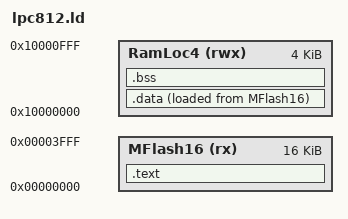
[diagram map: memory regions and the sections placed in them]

MEMORY
{
  /* Define each memory region */
  MFlash16 (rx) : ORIGIN = 0x0, LENGTH = 0x4000 /* 16k */
  RamLoc4 (rwx) : ORIGIN = 0x10000000, LENGTH = 0x1000 /* 4k */

}
  /* Define a symbol for the top of each memory region */
  __top_MFlash16 = 0x0 + 0x4000;
  __top_RamLoc4 = 0x10000000 + 0x1000;


ENTRY(ResetISR)

SECTIONS
{

    /* MAIN TEXT SECTION */    
    .text : ALIGN(4)
    {
        FILL(0xff)
        KEEP(*(.isr_vector))
        
        *(.after_vectors*)
        
        *(.text*)
        *(.rodata .rodata.*)
        . = ALIGN(4);
        
    } > MFlash16
    
    _etext = .;
        
    
    /* MAIN DATA SECTION */
    
    .data : ALIGN(4)
    {
        FILL(0xff)
        _data = .;
        *(vtable)
        *(.data*)
        . = ALIGN(4) ;
        _edata = .;
    } > RamLoc4 AT>MFlash16


    /* MAIN BSS SECTION */
    .bss : ALIGN(4)
    {
        _bss = .;
        *(.bss*)
        *(COMMON)
        . = ALIGN(4) ;
        _ebss = .;
        PROVIDE(end = .);
    } > RamLoc4
        
    
    PROVIDE(_pvHeapStart = .);
    PROVIDE(_vStackTop = __top_RamLoc4 - 0);
}
